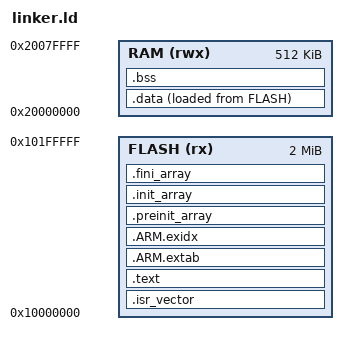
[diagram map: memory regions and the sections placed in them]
/* Copyright (C) 2026 32bitmicro LLC */
/* SPDX-License-Identifier: AGPL-3.0-or-later */

/*
 * RP2350 memory map (RP2350 datasheet): XIP flash base 0x10000000, main SRAM
 * banks (512K contiguous, conservative subset of the full 520K) at
 * 0x20000000. This places .isr_vector at the start of flash directly; it
 * does not emit or link against a second-stage bootloader (boot2), so it
 * will not boot from flash on real hardware or an RP2350 QEMU machine. See
 * docs/targets-arm/rp2040-rp2350.md.
 */

ENTRY(Reset_Handler)

MEMORY
{
    FLASH (rx)  : ORIGIN = 0x10000000, LENGTH = 2M
    RAM   (rwx) : ORIGIN = 0x20000000, LENGTH = 512K
}

_estack = ORIGIN(RAM) + LENGTH(RAM);

SECTIONS
{
    .isr_vector :
    {
        KEEP(*(.isr_vector))
    } > FLASH

    .text :
    {
        *(.text*)
        *(.rodata*)
        KEEP(*(.init))
        KEEP(*(.fini))
    } > FLASH

    .ARM.extab :
    {
        *(.ARM.extab* .gnu.linkonce.armextab.*)
    } > FLASH

    .ARM.exidx :
    {
        __exidx_start = .;
        *(.ARM.exidx* .gnu.linkonce.armexidx.*)
        __exidx_end = .;
    } > FLASH

    .preinit_array :
    {
        __preinit_array_start = .;
        KEEP(*(.preinit_array*))
        __preinit_array_end = .;
    } > FLASH

    .init_array :
    {
        __init_array_start = .;
        KEEP(*(SORT(.init_array.*)))
        KEEP(*(.init_array*))
        __init_array_end = .;
    } > FLASH

    .fini_array :
    {
        __fini_array_start = .;
        KEEP(*(SORT(.fini_array.*)))
        KEEP(*(.fini_array*))
        __fini_array_end = .;
    } > FLASH

    _sidata = LOADADDR(.data);

    .data :
    {
        _sdata = .;
        *(.data*)
        _edata = .;
    } > RAM AT > FLASH

    .bss (NOLOAD) :
    {
        _sbss = .;
        *(.bss*)
        *(COMMON)
        _ebss = .;
    } > RAM
}
